# PIC32CZ8110CA80176 device description
Architecture: CORTEX-M7; Family: PIC32C; Series: PIC32CZCA80
Registers are 32-bit, read-write, reset 0x0 unless marked. A register's access mark holds for its fields unless they carry their own. Offsets are from the block's base; [hi:lo] are bit positions; {n}, {i} and the like mark numbered series.

## FUSES_BOOTCFG1 — Defines FUSE parameters
Instances: FUSES_BOOTCFG1 0x0A002000, FUSES_BOOTCFG2 0x0A00A000
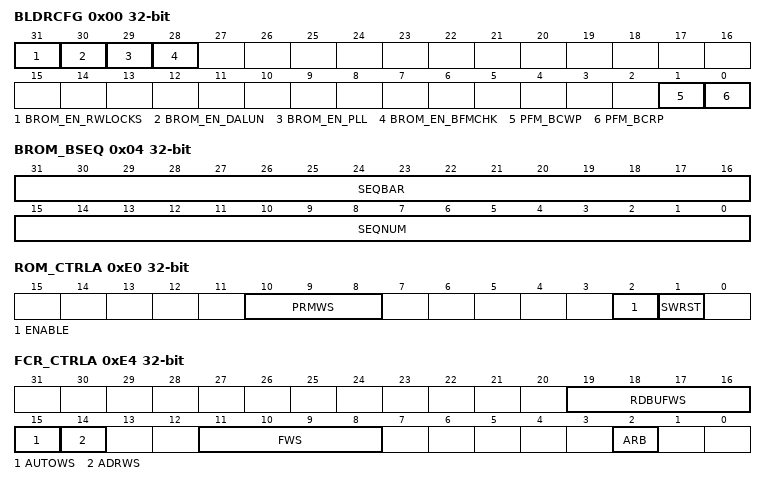
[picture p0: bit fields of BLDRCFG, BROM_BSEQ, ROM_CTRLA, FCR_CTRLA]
0x00 BLDRCFG reset not defined — Bootloader Configuration
  [31] BROM_EN_RWLOCKS — Enable Read/Write Locks
  [30] BROM_EN_DALUN — Enable DAL Unlock
  [29] BROM_EN_PLL — Enable PLL (Settings in PLL0_<REGS> are used)
  [28] BROM_EN_BFMCHK — Enable BFM CRC Check
    0=NONE (No verification); 1=CRC32 (Verify using crc32)
  [1] PFM_BCWP — Boot Configration Page Write Protect
  [0] PFM_BCRP — Boot Configration Page Read Protect
0x04 BROM_BSEQ reset not defined — Boot Configuraiton Page Sequence Number
  [31:16] SEQBAR — Sequence Number Bar (Negeated)
  [15:0] SEQNUM — Sequence Number
0x08 BFM_CHK_TABLEPTR reset not defined — BFM CRC Table Pointer
{0x80+4i} KEYVAL_TZ0_CE_ALL[{i}] (i=0..3) reset not defined — Chip Erase Key for TZ0_ALL
{0x90+4i} CELOCK_TZ0_CE_ALL[{i}] (i=0..3) reset not defined — Chip Erase Lock for TZ0_ALL
{0xA0+4i} KEYVAL_CRCCMD[{i}] (i=0..3) reset not defined — CRC Access Key
{0xB0+4i} KEYCONFIG_CRCCMD[{i}] (i=0..3) reset not defined — CRC Access Key Configuration
{0xC0+4i} KEYVAL_HOSTDALELEV[{i}] (i=0..3) reset not defined — Host Authenticated DAL Elevation Key
{0xD0+4i} KEYCONFIG_HOSTDALELEV[{i}] (i=0..3) reset not defined — Host Authenticated DAL Elevation Key Configuration
0xE0 ROM_CTRLA reset not defined — ROM CTRLA Settings (BROM_PLLEN must be set)
  [10:8] PRMWS — Wait States
  [2] ENABLE — Module Enable
  [1] SWRST — Software Reset
0xE4 FCR_CTRLA reset not defined — FCR CTRLA Settings (BROM_PLLEN must be set)
  [19:16] RDBUFWS — Data returned from the Read Buffer match the Flash Wait States
  [15] AUTOWS — Automatic Wait State Enable.
  [14] ADRWS — Address Wait State Enable
  [11:8] FWS — Flash Access Time Defined in terms of AHB Clock Wait States
  [2] ARB — AHB Arbitration scheme
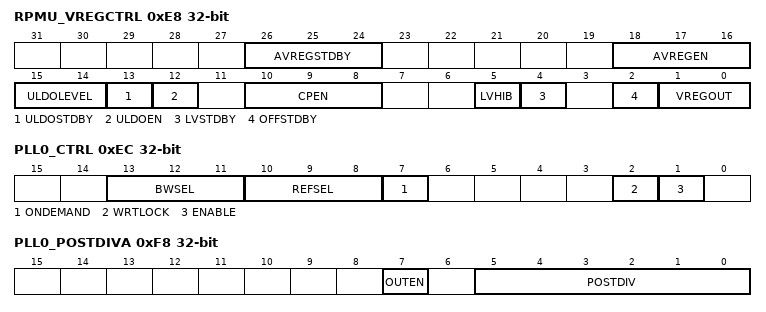
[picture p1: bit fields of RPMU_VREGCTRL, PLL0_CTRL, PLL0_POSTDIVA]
0xE8 RPMU_VREGCTRL reset not defined — RPMU VREGCTRL Settings (BROM_PLLEN must be set)
  [26:24] AVREGSTDBY — Additional Voltage Regulator Configuration
    0=OFFINSTDBY (Regulator is OFF while in sleep mode equal or deeper than standby mode. It is OFF in hibernate and backup mode as well.); 1=ONINSTDBY (Regulator is ON in Standby mode if AVREGEN bit is set. is OFF from Hibernate mode. It is OFF in backup mode as well.)
  [18:16] AVREGEN — Additional Voltage Regulator Enable
  [15:14] ULDOLEVEL — User LDO Voltage Level Selection
    0=1p2v (Vout = 1.2v); 1=1p5v (Vout = 1.5v); 2=1p8v (Vout = 1.8v); 3=2p5v (Vout = 2.5v)
  [13] ULDOSTDBY — User LDO Voltage Regulator Configuration
    0=OFFINSTDBY (Regulator is OFF while in sleep mode equal or deeper than standby mode. It is OFF in hibernate and backup mode as well.); 1=ONINSTDBY (Regulator is ON in Standby mode. is OFF from Hibernate mode. It is OFF in backup mode as well.)
  [12] ULDOEN — User LDO Voltage Regulator Enable
  [10:8] CPEN — Charge Pump Enable and Auto-enable.
  [5] LVHIB — Low Voltage Hibernate Enable
    0=1p2v (In Hibernate mode, VDDCORE_BU and VDDCORE_RAM are set to 1.2v.); 1=0p8v (In Hibernate mode, VDDCORE_BU and VDDCORE_RAM are set to 0.8v)
  [4] LVSTDBY — Low Voltage Standby Enable
    0=1p2v (In standby mode, VDDCORE_BU, VDDCORE_RAM, VDDCORE_SW and optionnaly VDDCOREUSB/PLL are set to 1.2v.); 1=0p8v (In standby mode, VDDCORE_BU, VDDCORE_RAM, VDDCORE_SW and optionnaly VDDCOREUSB/PLL are set to 0.8v.)
  [2] OFFSTDBY — Off in Standby Control for VREGSW[N-1]. Useful for Riverside only.
    0=OFF (In standby mode, VREGSW1,2,3 are OFF); 1=ON (In standby mode, VREGSW1,2,3 are ON)
  [1:0] VREGOUT — VREG Output Control in RUN mode only. Enable by production fuse by CALSUPC.VREGOUTEN
    0=1p2v (In Active mode, VDDCORE_RAM, VDDCORE_BU, VDDCORE_SW and optionnaly VDDCORE_PLL USB are set to 1.2v.); 1=1p0v (In Active mode, VDDCORE_RAM, VDDCORE_BU, VDDCORE_SW and optionnaly VDDCORE_PLL USB are set to 1.0v.); 2=0p8v (In Active mode, VDDCORE_RAM, VDDCORE_BU, VDDCORE_SW and optionnaly VDDCORE_PLL USB are set to 0.8v.)
0xEC PLL0_CTRL reset not defined — PLL0 CTRL Settings (BROM_PLLEN must be set)
  [13:11] BWSEL — Bandwidth selection
  [10:8] REFSEL — Reference selection
    0=GCLK (Dedicated GCLK clock reference); 1=XOSC (XOSC clock reference); 2=DFLL48M (DFLL48M clock reference)
  [7] ONDEMAND — On Demand Control
  [2] WRTLOCK — Write Lock
  [1] ENABLE — PLL Enable
0xF0 PLL0_FBDIV reset not defined — PLL0 FBDIV Settings (BROM_PLLEN must be set)
  [9:0] FBDIV — PLL Feed-Back Divider Factor
0xF4 PLL0_REFDIV reset not defined — PLL0 REFDIV Settings (BROM_PLLEN must be set)
  [5:0] REFDIV — PLL reference division factor
0xF8 PLL0_POSTDIVA reset not defined — PLL0 POSTDIVA Settings (BROM_PLLEN must be set)
  [7] OUTEN — PLL output 0 enable
  [5:0] POSTDIV — PLL output 0 clock division factor
0xFC MCLK_CLKDIV1 reset not defined — MCLK CLKDIV1 Settings (BROM_PLLEN must be set)
0x100 GCLK_GENCTRL0 reset not defined — GCLK GENCTRL0 Settings (BROM_PLLEN must be set)
{0x110+4i} BROM_BOOTCFGCRC[{i}] (i=0..3) reset not defined — Boot Configuraiton Page CRC
0x120 BROM_PAGEEND reset not defined — Page End Marker for Verified Data

## Notices in the file
Copyright (c) 2021 Microchip Technology Inc.
SPDX-License-Identifier: Apache-2.0
Licensed under the Apache License, Version 2.0 (the "License");
you may not use this file except in compliance with the License.
You may obtain a copy of the License at
http://www.apache.org/licenses/LICENSE-2.0
Unless required by applicable law or agreed to in writing, software
distributed under the License is distributed on an "AS IS" BASIS,
WITHOUT WARRANTIES OR CONDITIONS OF ANY KIND, either express or implied.
See the License for the specific language governing permissions and
limitations under the License.
